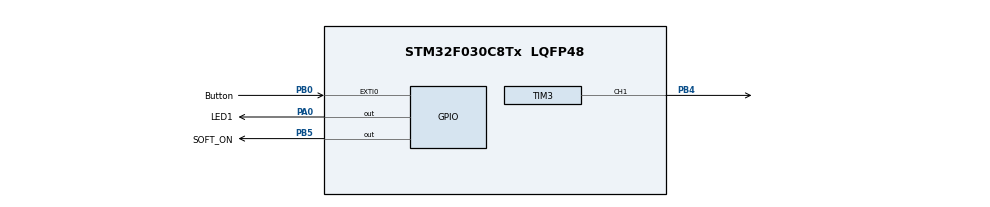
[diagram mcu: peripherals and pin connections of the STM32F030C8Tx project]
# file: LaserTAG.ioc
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Mcu.Family=STM32F0
Mcu.Name=STM32F030C8Tx
Mcu.Package=LQFP48
NVIC.EXTI0_1_IRQn=true\:0\:0\:false\:false\:true\:true\:true
PA0.GPIO_Label=LED1
PA0.GPIO_Speed=GPIO_SPEED_FREQ_HIGH
PA0.PinState=GPIO_PIN_RESET
PA0.Signal=GPIO_Output
PA13.Mode=Serial_Wire
PA13.Signal=SYS_SWDIO
PA14.Mode=Serial_Wire
PA14.Signal=SYS_SWCLK
PB0.GPIO_Label=Button
PB0.GPIO_ModeDefaultEXTI=GPIO_MODE_IT_FALLING
PB0.Signal=GPXTI0
PB4.Signal=S_TIM3_CH1
PB5.GPIO_Label=SOFT_ON
PB5.Signal=GPIO_Output
ProjectManager.HeapSize=0x200
ProjectManager.StackSize=0x400
ProjectManager.TargetToolchain=MDK-ARM V5.27
SH.S_TIM3_CH1.0=TIM3_CH1,PWM Generation1 CH1
TIM3.Channel-PWM\ Generation1\ CH1=TIM_CHANNEL_1
TIM3.Period=210
TIM3.Pulse-PWM\ Generation1\ CH1=105
VP_TIM3_VS_ClockSourceINT.Mode=Internal
board=custom

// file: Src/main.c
/* USER CODE BEGIN Header */
/**
  ******************************************************************************
  * @file           : main.c
  * @brief          : Main program body
  ******************************************************************************
  * @attention
  *
  * <h2><center>&copy; Copyright (c) 2020 STMicroelectronics.
  * All rights reserved.</center></h2>
  *
  * This software component is licensed by ST under BSD 3-Clause license,
  * the "License"; You may not use this file except in compliance with the
  * License. You may obtain a copy of the License at:
  *                        opensource.org/licenses/BSD-3-Clause
  *
  ******************************************************************************
  */
/* USER CODE END Header */

#include "main.h"
#include "tim.h"
#include "gpio.h"

/* USER CODE BEGIN PV */
extern uint8_t button_cl;
/* USER CODE END PV */

void SystemClock_Config(void);

int main(void)
{

  /* MCU Configuration--------------------------------------------------------*/

  /* Reset of all peripherals, Initializes the Flash interface and the Systick. */
  HAL_Init();

  /* Configure the system clock */
  SystemClock_Config();

  /* Initialize all configured peripherals */
  MX_GPIO_Init();
  MX_TIM3_Init();
  /* USER CODE BEGIN 2 */
	HAL_TIM_Base_Start_IT(&htim3);
  /* USER CODE END 2 */

  /* Infinite loop */
  /* USER CODE BEGIN WHILE */
  while (1)
  {
		if(button_cl == 1)
		{
			HAL_GPIO_WritePin(SOFT_ON_GPIO_Port, SOFT_ON_Pin, GPIO_PIN_SET);
			HAL_Delay(1);
			HAL_TIM_PWM_Start(&htim3, TIM_CHANNEL_1);
			HAL_GPIO_WritePin(LED1_GPIO_Port, LED1_Pin, GPIO_PIN_SET);
		}
		else if(button_cl == 2)
		{
			button_cl = 0;
			HAL_TIM_PWM_Stop(&htim3, TIM_CHANNEL_1);
			HAL_Delay(1);
			HAL_GPIO_WritePin(SOFT_ON_GPIO_Port, SOFT_ON_Pin, GPIO_PIN_RESET);
			HAL_GPIO_WritePin(LED1_GPIO_Port, LED1_Pin, GPIO_PIN_RESET);
		}
    /* USER CODE END WHILE */

  }
}

void SystemClock_Config(void)
{
  RCC_OscInitTypeDef RCC_OscInitStruct = {0};
  RCC_ClkInitTypeDef RCC_ClkInitStruct = {0};

  /** Initializes the CPU, AHB and APB busses clocks
  */
  RCC_OscInitStruct.OscillatorType = RCC_OSCILLATORTYPE_HSI;
  RCC_OscInitStruct.HSIState = RCC_HSI_ON;
  RCC_OscInitStruct.HSICalibrationValue = RCC_HSICALIBRATION_DEFAULT;
  RCC_OscInitStruct.PLL.PLLState = RCC_PLL_NONE;
  if (HAL_RCC_OscConfig(&RCC_OscInitStruct) != HAL_OK)
  {
    Error_Handler();
  }
  /** Initializes the CPU, AHB and APB busses clocks
  */
  RCC_ClkInitStruct.ClockType = RCC_CLOCKTYPE_HCLK|RCC_CLOCKTYPE_SYSCLK
                              |RCC_CLOCKTYPE_PCLK1;
  RCC_ClkInitStruct.SYSCLKSource = RCC_SYSCLKSOURCE_HSI;
  RCC_ClkInitStruct.AHBCLKDivider = RCC_SYSCLK_DIV1;
  RCC_ClkInitStruct.APB1CLKDivider = RCC_HCLK_DIV1;

  if (HAL_RCC_ClockConfig(&RCC_ClkInitStruct, FLASH_LATENCY_0) != HAL_OK)
  {
    Error_Handler();
  }
}

void Error_Handler(void)
{
}

/************************ (C) COPYRIGHT STMicroelectronics *****END OF FILE****/
